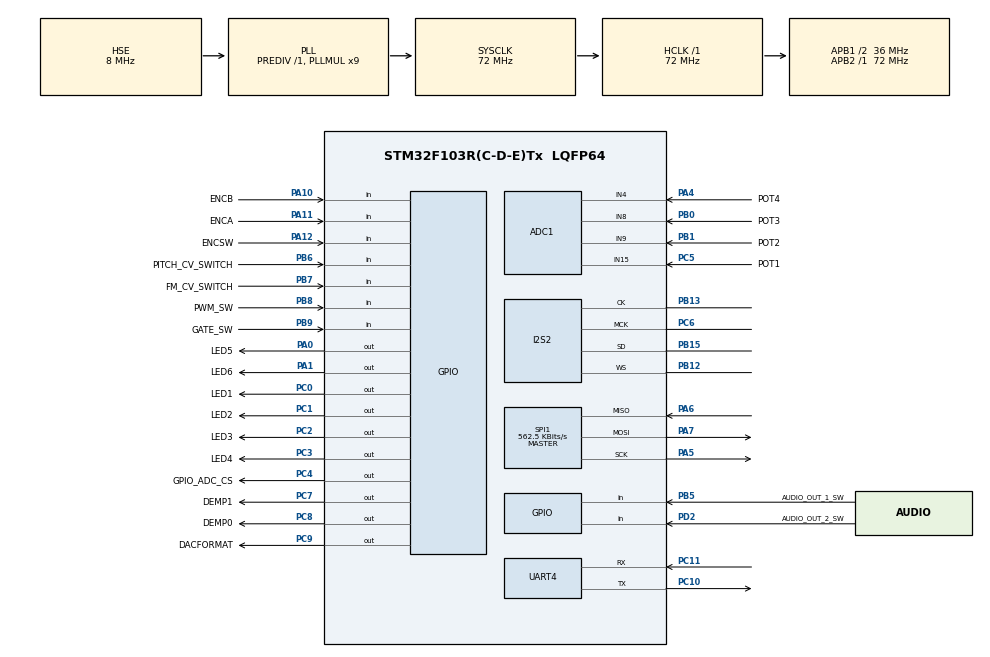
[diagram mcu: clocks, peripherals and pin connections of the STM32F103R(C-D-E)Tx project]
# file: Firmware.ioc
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ADC1.Channel-1\#ChannelRegularConversion=ADC_CHANNEL_8
ADC1.ContinuousConvMode=ENABLE
ADC1.NbrOfConversionFlag=1
ADC1.Rank-1\#ChannelRegularConversion=1
ADC1.SamplingTime-1\#ChannelRegularConversion=ADC_SAMPLETIME_1CYCLE_5
ADC1.master=1
Dma.ADC1.0.Direction=DMA_PERIPH_TO_MEMORY
Dma.ADC1.0.Instance=DMA1_Channel1
Dma.ADC1.0.MemDataAlignment=DMA_MDATAALIGN_HALFWORD
Dma.ADC1.0.MemInc=DMA_MINC_ENABLE
Dma.ADC1.0.Mode=DMA_CIRCULAR
Dma.ADC1.0.PeriphDataAlignment=DMA_PDATAALIGN_HALFWORD
Dma.ADC1.0.PeriphInc=DMA_PINC_DISABLE
Dma.ADC1.0.Priority=DMA_PRIORITY_MEDIUM
Dma.Request0=ADC1
Dma.Request1=SPI2_TX
Dma.SPI2_TX.1.Direction=DMA_MEMORY_TO_PERIPH
Dma.SPI2_TX.1.Instance=DMA1_Channel5
Dma.SPI2_TX.1.MemDataAlignment=DMA_MDATAALIGN_BYTE
Dma.SPI2_TX.1.MemInc=DMA_MINC_ENABLE
Dma.SPI2_TX.1.Mode=DMA_CIRCULAR
Dma.SPI2_TX.1.PeriphDataAlignment=DMA_PDATAALIGN_HALFWORD
Dma.SPI2_TX.1.PeriphInc=DMA_PINC_DISABLE
Dma.SPI2_TX.1.Priority=DMA_PRIORITY_VERY_HIGH
I2S2.AudioFreq=I2S_AUDIOFREQ_48K
I2S2.ErrorAudioFreq=-2.34 %
I2S2.Instance=SPI$Index
I2S2.MCLKOutput=I2S_MCLKOUTPUT_ENABLE
I2S2.RealAudioFreq=46.875 KHz
I2S2.VirtualMode=I2S_MODE_MASTER
Mcu.Family=STM32F1
Mcu.Name=STM32F103R(C-D-E)Tx
Mcu.Package=LQFP64
NVIC.DMA1_Channel1_IRQn=true\:0\:0\:false\:false\:true\:false\:true
NVIC.DMA1_Channel5_IRQn=true\:0\:0\:false\:false\:true\:false\:true
NVIC.PriorityGroup=NVIC_PRIORITYGROUP_4
PA0-WKUP.GPIO_Label=LED5
PA0-WKUP.Signal=GPIO_Output
PA1.GPIO_Label=LED6
PA1.Signal=GPIO_Output
PA10.GPIO_Label=ENCB
PA10.Signal=GPIO_Input
PA11.GPIO_Label=ENCA
PA11.Signal=GPIO_Input
PA12.GPIO_Label=ENCSW
PA12.Signal=GPIO_Input
PA13.Mode=Serial_Wire
PA13.Signal=SYS_JTMS-SWDIO
PA14.Mode=Serial_Wire
PA14.Signal=SYS_JTCK-SWCLK
PA4.GPIO_Label=POT4
PA4.Signal=ADCx_IN4
PA5.Mode=Full_Duplex_Master
PA5.Signal=SPI1_SCK
PA6.Mode=Full_Duplex_Master
PA6.Signal=SPI1_MISO
PA7.Mode=Full_Duplex_Master
PA7.Signal=SPI1_MOSI
PB0.GPIO_Label=POT3
PB0.Signal=ADCx_IN8
PB1.GPIO_Label=POT2
PB1.Signal=ADCx_IN9
PB12.Mode=Half_Duplex_Master_TX
PB12.Signal=I2S2_WS
PB13.Mode=Half_Duplex_Master_TX
PB13.Signal=I2S2_CK
PB15.Mode=Half_Duplex_Master_TX
PB15.Signal=I2S2_SD
PB5.GPIO_Label=AUDIO_OUT_1_SW
PB5.Signal=GPIO_Input
PB6.GPIO_Label=PITCH_CV_SWITCH
PB6.Signal=GPIO_Input
PB7.GPIO_Label=FM_CV_SWITCH
PB7.Signal=GPIO_Input
PB8.GPIO_Label=PWM_SW
PB8.Signal=GPIO_Input
PB9.GPIO_Label=GATE_SW
PB9.Signal=GPIO_Input
PC0.GPIO_Label=LED1
PC0.Signal=GPIO_Output
PC1.GPIO_Label=LED2
PC1.Signal=GPIO_Output
PC10.Mode=Asynchronous
PC10.Signal=UART4_TX
PC11.Mode=Asynchronous
PC11.Signal=UART4_RX
PC2.GPIO_Label=LED3
PC2.Signal=GPIO_Output
PC3.GPIO_Label=LED4
PC3.Signal=GPIO_Output
PC4.GPIO_Label=GPIO_ADC_CS
PC4.Signal=GPIO_Output
PC5.GPIO_Label=POT1
PC5.Signal=ADCx_IN15
PC6.Mode=Master_Clock_Activated
PC6.Signal=I2S2_MCK
PC7.GPIO_Label=DEMP1
PC7.Signal=GPIO_Output
PC8.GPIO_Label=DEMP0
PC8.Signal=GPIO_Output
PC9.GPIO_Label=DACFORMAT
PC9.Signal=GPIO_Output
PD0-OSC_IN.Mode=HSE-External-Oscillator
PD0-OSC_IN.Signal=RCC_OSC_IN
PD1-OSC_OUT.Mode=HSE-External-Oscillator
PD1-OSC_OUT.Signal=RCC_OSC_OUT
PD2.GPIO_Label=AUDIO_OUT_2_SW
PD2.Signal=GPIO_Input
ProjectManager.HeapSize=0x200
ProjectManager.StackSize=0x400
ProjectManager.TargetToolchain=Makefile
RCC.ADCPresc=RCC_ADCPCLK2_DIV6
RCC.AHBFreq_Value=72000000
RCC.APB1CLKDivider=RCC_HCLK_DIV2
RCC.APB1Freq_Value=36000000
RCC.APB1TimFreq_Value=72000000
RCC.APB2Freq_Value=72000000
RCC.APB2TimFreq_Value=72000000
RCC.HCLKFreq_Value=72000000
RCC.PLLMUL=RCC_PLL_MUL9
RCC.PLLSourceVirtual=RCC_PLLSOURCE_HSE
RCC.SYSCLKFreq_VALUE=72000000
RCC.SYSCLKSource=RCC_SYSCLKSOURCE_PLLCLK
RCC.USBFreq_Value=72000000
SH.ADCx_IN15.0=ADC1_IN15,IN15
SH.ADCx_IN4.0=ADC1_IN4,IN4
SH.ADCx_IN8.0=ADC1_IN8,IN8
SH.ADCx_IN9.0=ADC1_IN9,IN9
SPI1.BaudRatePrescaler=SPI_BAUDRATEPRESCALER_128
SPI1.CalculateBaudRate=562.5 KBits/s
SPI1.Direction=SPI_DIRECTION_2LINES
SPI1.Mode=SPI_MODE_MASTER
SPI1.VirtualType=VM_MASTER
UART4.VirtualMode=Asynchronous
VP_TIM6_VS_ClockSourceINT.Mode=Enable_Timer
board=custom

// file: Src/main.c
/* USER CODE BEGIN Header */
/**
  ******************************************************************************
  * @file           : main.c
  * @brief          : Main program body
  ******************************************************************************
  * @attention
  *
  * <h2><center>&copy; Copyright (c) 2020 STMicroelectronics.
  * All rights reserved.</center></h2>
  *
  * This software component is licensed by ST under BSD 3-Clause license,
  * the "License"; You may not use this file except in compliance with the
  * License. You may obtain a copy of the License at:
  *                        opensource.org/licenses/BSD-3-Clause
  *
  ******************************************************************************
  */
/* USER CODE END Header */

#include "main.h"

/* USER CODE BEGIN Includes */
#include "mcp3204.h"
#include "DSPmain.h"
#include "stm32_HAL.h"
#include "interfaces.h"
// extern uint32_t potVals[4];
/* USER CODE END Includes */

/* USER CODE BEGIN PTD */
uint16_t pot1, pot2, pot3, pot4;
uint16_t adcbuf[4];
// extern uint8_t jackStatus[6];
/* USER CODE END PTD */

ADC_HandleTypeDef hadc1;
DMA_HandleTypeDef hdma_adc1;

I2S_HandleTypeDef hi2s2;
DMA_HandleTypeDef hdma_spi2_tx;

SPI_HandleTypeDef hspi1;

TIM_HandleTypeDef htim6;

UART_HandleTypeDef huart4;

/* USER CODE BEGIN PV */
HAL_ADC_ConvCpltCallback(ADC_HandleTypeDef* hadc){
  for (int i = 0; i < 4; i++)
  {
    potVals[i] = adcbuf[i];
  }

}
/* USER CODE END PV */

void SystemClock_Config(void);
static void MX_GPIO_Init(void);
static void MX_DMA_Init(void);
static void MX_ADC1_Init(void);
static void MX_I2S2_Init(void);
static void MX_SPI1_Init(void);
static void MX_UART4_Init(void);
static void MX_TIM6_Init(void);

int main(void)
{
  /* USER CODE BEGIN 1 */
  // adcRead(1);
  /* USER CODE END 1 */

  /* MCU Configuration--------------------------------------------------------*/

  /* Reset of all peripherals, Initializes the Flash interface and the Systick. */
  HAL_Init();

  /* Configure the system clock */
  SystemClock_Config();

  /* Initialize all configured peripherals */
  MX_GPIO_Init();
  MX_DMA_Init();
  MX_ADC1_Init();
  MX_I2S2_Init();
  MX_SPI1_Init();
  MX_UART4_Init();
  MX_TIM6_Init();
  /* USER CODE BEGIN 2 */
  HAL_TIM_Base_Start_IT(&htim6);
  // HAL_ADCEx_Calibration_Start(&hadc1);
  HAL_ADC_Start_DMA(&hadc1, adcbuf, 4);
  // HAL_ADC_PollForConversion(&hadc1, HAL_MAX_DELAY);
  uint16_t raw;
  /* USER CODE END 2 */

  /* Infinite loop */
  while (1)
  {

    /* USER CODE BEGIN 3 */
    // pot1 = potVals[Pot1];
    // pot2 = potVals[Pot2];
    // pot3 = potVals[Pot3];
    // pot4 = potVals[Pot4];

    updateJackStatus();

  }
  /* USER CODE END 3 */
}

void SystemClock_Config(void)
{
  RCC_OscInitTypeDef RCC_OscInitStruct = {0};
  RCC_ClkInitTypeDef RCC_ClkInitStruct = {0};
  RCC_PeriphCLKInitTypeDef PeriphClkInit = {0};

  /** Initializes the CPU, AHB and APB busses clocks
  */
  RCC_OscInitStruct.OscillatorType = RCC_OSCILLATORTYPE_HSE;
  RCC_OscInitStruct.HSEState = RCC_HSE_ON;
  RCC_OscInitStruct.HSEPredivValue = RCC_HSE_PREDIV_DIV1;
  RCC_OscInitStruct.HSIState = RCC_HSI_ON;
  RCC_OscInitStruct.PLL.PLLState = RCC_PLL_ON;
  RCC_OscInitStruct.PLL.PLLSource = RCC_PLLSOURCE_HSE;
  RCC_OscInitStruct.PLL.PLLMUL = RCC_PLL_MUL9;
  if (HAL_RCC_OscConfig(&RCC_OscInitStruct) != HAL_OK)
  {
    Error_Handler();
  }
  /** Initializes the CPU, AHB and APB busses clocks
  */
  RCC_ClkInitStruct.ClockType = RCC_CLOCKTYPE_HCLK|RCC_CLOCKTYPE_SYSCLK
                              |RCC_CLOCKTYPE_PCLK1|RCC_CLOCKTYPE_PCLK2;
  RCC_ClkInitStruct.SYSCLKSource = RCC_SYSCLKSOURCE_PLLCLK;
  RCC_ClkInitStruct.AHBCLKDivider = RCC_SYSCLK_DIV1;
  RCC_ClkInitStruct.APB1CLKDivider = RCC_HCLK_DIV2;
  RCC_ClkInitStruct.APB2CLKDivider = RCC_HCLK_DIV1;

  if (HAL_RCC_ClockConfig(&RCC_ClkInitStruct, FLASH_LATENCY_2) != HAL_OK)
  {
    Error_Handler();
  }
  PeriphClkInit.PeriphClockSelection = RCC_PERIPHCLK_ADC|RCC_PERIPHCLK_I2S2;
  PeriphClkInit.AdcClockSelection = RCC_ADCPCLK2_DIV6;
  PeriphClkInit.I2s2ClockSelection = RCC_I2S2CLKSOURCE_SYSCLK;
  if (HAL_RCCEx_PeriphCLKConfig(&PeriphClkInit) != HAL_OK)
  {
    Error_Handler();
  }
}

static void MX_ADC1_Init(void)
{

  ADC_ChannelConfTypeDef sConfig = {0};

  /** Common config
  */
  hadc1.Instance = ADC1;
  hadc1.Init.ScanConvMode = ADC_SCAN_DISABLE;
  hadc1.Init.ContinuousConvMode = ENABLE;
  hadc1.Init.DiscontinuousConvMode = DISABLE;
  hadc1.Init.ExternalTrigConv = ADC_SOFTWARE_START;
  hadc1.Init.DataAlign = ADC_DATAALIGN_RIGHT;
  hadc1.Init.NbrOfConversion = 1;
  if (HAL_ADC_Init(&hadc1) != HAL_OK)
  {
    Error_Handler();
  }
  /** Configure Regular Channel
  */
  sConfig.Channel = ADC_CHANNEL_8;
  sConfig.Rank = ADC_REGULAR_RANK_1;
  sConfig.SamplingTime = ADC_SAMPLETIME_1CYCLE_5;
  if (HAL_ADC_ConfigChannel(&hadc1, &sConfig) != HAL_OK)
  {
    Error_Handler();
  }

}

static void MX_I2S2_Init(void)
{

  hi2s2.Instance = SPI2;
  hi2s2.Init.Mode = I2S_MODE_MASTER_TX;
  hi2s2.Init.Standard = I2S_STANDARD_PHILIPS;
  hi2s2.Init.DataFormat = I2S_DATAFORMAT_16B;
  hi2s2.Init.MCLKOutput = I2S_MCLKOUTPUT_ENABLE;
  hi2s2.Init.AudioFreq = I2S_AUDIOFREQ_48K;
  hi2s2.Init.CPOL = I2S_CPOL_LOW;
  if (HAL_I2S_Init(&hi2s2) != HAL_OK)
  {
    Error_Handler();
  }

}

static void MX_SPI1_Init(void)
{

  /* SPI1 parameter configuration*/
  hspi1.Instance = SPI1;
  hspi1.Init.Mode = SPI_MODE_MASTER;
  hspi1.Init.Direction = SPI_DIRECTION_2LINES;
  hspi1.Init.DataSize = SPI_DATASIZE_8BIT;
  hspi1.Init.CLKPolarity = SPI_POLARITY_LOW;
  hspi1.Init.CLKPhase = SPI_PHASE_1EDGE;
  hspi1.Init.NSS = SPI_NSS_SOFT;
  hspi1.Init.BaudRatePrescaler = SPI_BAUDRATEPRESCALER_128;
  hspi1.Init.FirstBit = SPI_FIRSTBIT_MSB;
  hspi1.Init.TIMode = SPI_TIMODE_DISABLE;
  hspi1.Init.CRCCalculation = SPI_CRCCALCULATION_DISABLE;
  hspi1.Init.CRCPolynomial = 10;
  if (HAL_SPI_Init(&hspi1) != HAL_OK)
  {
    Error_Handler();
  }

}

static void MX_TIM6_Init(void)
{

  TIM_MasterConfigTypeDef sMasterConfig = {0};

  htim6.Instance = TIM6;
  htim6.Init.Prescaler = 0;
  htim6.Init.CounterMode = TIM_COUNTERMODE_UP;
  htim6.Init.Period = 0;
  htim6.Init.AutoReloadPreload = TIM_AUTORELOAD_PRELOAD_DISABLE;
  if (HAL_TIM_Base_Init(&htim6) != HAL_OK)
  {
    Error_Handler();
  }
  sMasterConfig.MasterOutputTrigger = TIM_TRGO_RESET;
  sMasterConfig.MasterSlaveMode = TIM_MASTERSLAVEMODE_DISABLE;
  if (HAL_TIMEx_MasterConfigSynchronization(&htim6, &sMasterConfig) != HAL_OK)
  {
    Error_Handler();
  }

}

static void MX_UART4_Init(void)
{

  huart4.Instance = UART4;
  huart4.Init.BaudRate = 115200;
  huart4.Init.WordLength = UART_WORDLENGTH_8B;
  huart4.Init.StopBits = UART_STOPBITS_1;
  huart4.Init.Parity = UART_PARITY_NONE;
  huart4.Init.Mode = UART_MODE_TX_RX;
  huart4.Init.HwFlowCtl = UART_HWCONTROL_NONE;
  huart4.Init.OverSampling = UART_OVERSAMPLING_16;
  if (HAL_UART_Init(&huart4) != HAL_OK)
  {
    Error_Handler();
  }

}

static void MX_DMA_Init(void)
{

  /* DMA controller clock enable */
  __HAL_RCC_DMA1_CLK_ENABLE();

  /* DMA interrupt init */
  /* DMA1_Channel1_IRQn interrupt configuration */
  HAL_NVIC_SetPriority(DMA1_Channel1_IRQn, 0, 0);
  HAL_NVIC_EnableIRQ(DMA1_Channel1_IRQn);
  /* DMA1_Channel5_IRQn interrupt configuration */
  HAL_NVIC_SetPriority(DMA1_Channel5_IRQn, 0, 0);
  HAL_NVIC_EnableIRQ(DMA1_Channel5_IRQn);

}

static void MX_GPIO_Init(void)
{
  GPIO_InitTypeDef GPIO_InitStruct = {0};

  /* GPIO Ports Clock Enable */
  __HAL_RCC_GPIOD_CLK_ENABLE();
  __HAL_RCC_GPIOC_CLK_ENABLE();
  __HAL_RCC_GPIOA_CLK_ENABLE();
  __HAL_RCC_GPIOB_CLK_ENABLE();

  /*Configure GPIO pin Output Level */
  HAL_GPIO_WritePin(GPIOC, LED1_Pin|LED2_Pin|LED3_Pin|LED4_Pin
                          |GPIO_ADC_CS_Pin|DEMP1_Pin|DEMP0_Pin|DACFORMAT_Pin, GPIO_PIN_RESET);

  /*Configure GPIO pin Output Level */
  HAL_GPIO_WritePin(GPIOA, LED5_Pin|LED6_Pin, GPIO_PIN_RESET);

  /*Configure GPIO pins : LED1_Pin LED2_Pin LED3_Pin LED4_Pin
                           GPIO_ADC_CS_Pin DEMP1_Pin DEMP0_Pin DACFORMAT_Pin */
  GPIO_InitStruct.Pin = LED1_Pin|LED2_Pin|LED3_Pin|LED4_Pin
                          |GPIO_ADC_CS_Pin|DEMP1_Pin|DEMP0_Pin|DACFORMAT_Pin;
  GPIO_InitStruct.Mode = GPIO_MODE_OUTPUT_PP;
  GPIO_InitStruct.Pull = GPIO_NOPULL;
  GPIO_InitStruct.Speed = GPIO_SPEED_FREQ_LOW;
  HAL_GPIO_Init(GPIOC, &GPIO_InitStruct);

  /*Configure GPIO pins : LED5_Pin LED6_Pin */
  GPIO_InitStruct.Pin = LED5_Pin|LED6_Pin;
  GPIO_InitStruct.Mode = GPIO_MODE_OUTPUT_PP;
  GPIO_InitStruct.Pull = GPIO_NOPULL;
  GPIO_InitStruct.Speed = GPIO_SPEED_FREQ_LOW;
  HAL_GPIO_Init(GPIOA, &GPIO_InitStruct);

  /*Configure GPIO pins : ENCB_Pin ENCA_Pin ENCSW_Pin */
  GPIO_InitStruct.Pin = ENCB_Pin|ENCA_Pin|ENCSW_Pin;
  GPIO_InitStruct.Mode = GPIO_MODE_INPUT;
  GPIO_InitStruct.Pull = GPIO_NOPULL;
  HAL_GPIO_Init(GPIOA, &GPIO_InitStruct);

  /*Configure GPIO pin : AUDIO_OUT_2_SW_Pin */
  GPIO_InitStruct.Pin = AUDIO_OUT_2_SW_Pin;
  GPIO_InitStruct.Mode = GPIO_MODE_INPUT;
  GPIO_InitStruct.Pull = GPIO_NOPULL;
  HAL_GPIO_Init(AUDIO_OUT_2_SW_GPIO_Port, &GPIO_InitStruct);

  /*Configure GPIO pins : AUDIO_OUT_1_SW_Pin PITCH_CV_SWITCH_Pin FM_CV_SWITCH_Pin PWM_SW_Pin
                           GATE_SW_Pin */
  GPIO_InitStruct.Pin = AUDIO_OUT_1_SW_Pin|PITCH_CV_SWITCH_Pin|FM_CV_SWITCH_Pin|PWM_SW_Pin
                          |GATE_SW_Pin;
  GPIO_InitStruct.Mode = GPIO_MODE_INPUT;
  GPIO_InitStruct.Pull = GPIO_NOPULL;
  HAL_GPIO_Init(GPIOB, &GPIO_InitStruct);

}

void Error_Handler(void)
{
}

/************************ (C) COPYRIGHT STMicroelectronics *****END OF FILE****/
